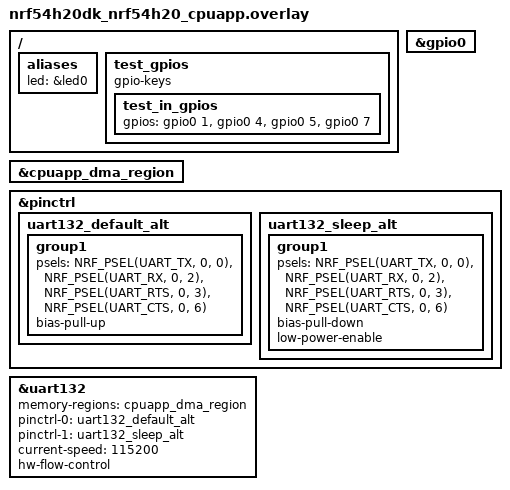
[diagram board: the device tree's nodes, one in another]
/*
 * Copyright (c) 2026 Nordic Semiconductor ASA
 *
 * SPDX-License-Identifier: LicenseRef-Nordic-5-Clause
 */

/*
 * Required loopbacks
 * P0.00 - P0.01
 * P0.02 - P0.04
 * P0.03 - P0.05
 * P0.06 - P0.07
 */

/ {
	aliases {
		led = &led0;
		/delete-property/ led1;
	};

	test_gpios {
		compatible = "gpio-keys";

		test_in_gpios: test_in_gpios {
			gpios = <&gpio0 1 GPIO_ACTIVE_HIGH>, <&gpio0 4 GPIO_ACTIVE_HIGH>,
				<&gpio0 5 GPIO_ACTIVE_HIGH>, <&gpio0 7 GPIO_ACTIVE_HIGH>;
		};
	};
};

/delete-node/ &led1;

&gpio0 {
	status = "okay";
};

&cpuapp_dma_region {
	status = "okay";
};

&pinctrl {
	uart132_default_alt: uart132_default_alt {
		group1 {
			psels = <NRF_PSEL(UART_TX, 0, 0)>,
				<NRF_PSEL(UART_RX, 0, 2)>,
				<NRF_PSEL(UART_RTS, 0, 3)>,
				<NRF_PSEL(UART_CTS, 0, 6)>;
			bias-pull-up;
		};
	};

	uart132_sleep_alt: uart132_sleep_alt {
		group1 {
			psels = <NRF_PSEL(UART_TX, 0, 0)>,
				<NRF_PSEL(UART_RX, 0, 2)>,
				<NRF_PSEL(UART_RTS, 0, 3)>,
				<NRF_PSEL(UART_CTS, 0, 6)>;
			bias-pull-down;
			low-power-enable;
		};
	};
};

dut: &uart132 {
	status = "okay";
	memory-regions = <&cpuapp_dma_region>;
	pinctrl-0 = <&uart132_default_alt>;
	pinctrl-1 = <&uart132_sleep_alt>;
	pinctrl-names = "default", "sleep";
	current-speed = <115200>;
	hw-flow-control;
	/delete-property/ zephyr,pm-device-runtime-auto;
};
